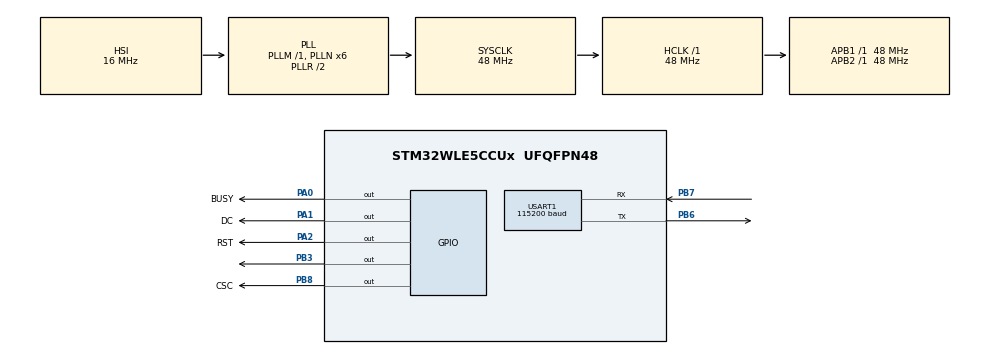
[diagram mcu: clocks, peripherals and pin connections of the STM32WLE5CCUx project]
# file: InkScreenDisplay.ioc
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Dma.Request0=USART1_RX
Dma.Request1=USART1_TX
Dma.USART1_RX.0.Direction=DMA_PERIPH_TO_MEMORY
Dma.USART1_RX.0.EventEnable=DISABLE
Dma.USART1_RX.0.Instance=DMA1_Channel1
Dma.USART1_RX.0.MemDataAlignment=DMA_MDATAALIGN_BYTE
Dma.USART1_RX.0.MemInc=DMA_MINC_ENABLE
Dma.USART1_RX.0.Mode=DMA_NORMAL
Dma.USART1_RX.0.PeriphDataAlignment=DMA_PDATAALIGN_BYTE
Dma.USART1_RX.0.PeriphInc=DMA_PINC_DISABLE
Dma.USART1_RX.0.Polarity=HAL_DMAMUX_REQ_GEN_RISING
Dma.USART1_RX.0.Priority=DMA_PRIORITY_HIGH
Dma.USART1_RX.0.RequestNumber=1
Dma.USART1_RX.0.SignalID=NONE
Dma.USART1_RX.0.SyncEnable=DISABLE
Dma.USART1_RX.0.SyncPolarity=HAL_DMAMUX_SYNC_NO_EVENT
Dma.USART1_RX.0.SyncRequestNumber=1
Dma.USART1_RX.0.SyncSignalID=NONE
Dma.USART1_TX.1.Direction=DMA_MEMORY_TO_PERIPH
Dma.USART1_TX.1.EventEnable=DISABLE
Dma.USART1_TX.1.Instance=DMA1_Channel2
Dma.USART1_TX.1.MemDataAlignment=DMA_MDATAALIGN_BYTE
Dma.USART1_TX.1.MemInc=DMA_MINC_ENABLE
Dma.USART1_TX.1.Mode=DMA_NORMAL
Dma.USART1_TX.1.PeriphDataAlignment=DMA_PDATAALIGN_BYTE
Dma.USART1_TX.1.PeriphInc=DMA_PINC_DISABLE
Dma.USART1_TX.1.Polarity=HAL_DMAMUX_REQ_GEN_RISING
Dma.USART1_TX.1.Priority=DMA_PRIORITY_LOW
Dma.USART1_TX.1.RequestNumber=1
Dma.USART1_TX.1.SignalID=NONE
Dma.USART1_TX.1.SyncEnable=DISABLE
Dma.USART1_TX.1.SyncPolarity=HAL_DMAMUX_SYNC_NO_EVENT
Dma.USART1_TX.1.SyncRequestNumber=1
Dma.USART1_TX.1.SyncSignalID=NONE
Mcu.Family=STM32WL
Mcu.Name=STM32WLE5CCUx
Mcu.Package=UFQFPN48
NVIC.DMA1_Channel1_IRQn=true\:0\:0\:false\:false\:true\:false\:true\:true
NVIC.DMA1_Channel2_IRQn=true\:0\:0\:false\:false\:true\:false\:true\:true
NVIC.PriorityGroup=NVIC_PRIORITYGROUP_4
NVIC.USART1_IRQn=true\:0\:0\:false\:false\:true\:true\:true\:true
PA0.GPIO_Label=BUSY
PA0.Signal=GPIO_Output
PA1.GPIO_Label=DC
PA1.Signal=GPIO_Output
PA13.Mode=Serial_Wire
PA13.Signal=DEBUG_JTMS-SWDIO
PA14.Mode=Serial_Wire
PA14.Signal=DEBUG_JTCK-SWCLK
PA2.GPIO_Label=RST
PA2.Signal=GPIO_Output
PB3.Signal=GPIO_Output
PB6.Mode=Asynchronous
PB6.Signal=USART1_TX
PB7.Mode=Asynchronous
PB7.Signal=USART1_RX
PB8.GPIO_Label=CSC
PB8.Signal=GPIO_Output
ProjectManager.HeapSize=0x200
ProjectManager.StackSize=0x400
ProjectManager.TargetToolchain=MDK-ARM V5.37
RCC.AHBFreq_Value=48000000
RCC.APB1Freq_Value=48000000
RCC.APB1TimFreq_Value=48000000
RCC.APB2Freq_Value=48000000
RCC.APB2TimFreq_Value=48000000
RCC.APB3Freq_Value=48000000
RCC.CortexFreq_Value=48000000
RCC.HCLKFreq_Value=48000000
RCC.HSE_VALUE=16000000
RCC.HSI_VALUE=16000000
RCC.LSE_VALUE=32768
RCC.LSIDIV=RCC_LSI_DIV128
RCC.MSIClockRange=RCC_MSIRANGE_0
RCC.PLLN=6
RCC.PLLSourceVirtual=RCC_PLLSOURCE_HSI
RCC.SYSCLKFreq_VALUE=48000000
RCC.SYSCLKSource=RCC_SYSCLKSOURCE_PLLCLK
RCC.USART1CLockSelection=RCC_USART1CLKSOURCE_SYSCLK
RCC.VCOOutputFreq_Value=96000000
USART1.BaudRate=115200
USART1.VirtualMode-Asynchronous=VM_ASYNC
board=custom

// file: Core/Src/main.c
/* USER CODE BEGIN Header */
/**
 ******************************************************************************
 * @file           : main.c
 * @brief          : Main program body
 ******************************************************************************
 * @attention
 *
 * Copyright (c) 2024 STMicroelectronics.
 * All rights reserved.
 *
 * This software is licensed under terms that can be found in the LICENSE file
 * in the root directory of this software component.
 * If no LICENSE file comes with this software, it is provided AS-IS.
 *
 ******************************************************************************
 */
/* USER CODE END Header */
#include "main.h"
#include "dma.h"
#include "usart.h"
#include "gpio.h"

/* USER CODE BEGIN Includes */
#include <string.h>
/* USER CODE END Includes */

void SystemClock_Config(void);
/* USER CODE BEGIN PFP */
int fputc( int ch, FILE* f ) {
    HAL_UART_Transmit( &huart1, ( uint8_t* )&ch, 1, 0xffff );
    return ch;
}

int fgetc( FILE* f ) {
    uint8_t ch = 0;
    HAL_UART_Receive( &huart1, &ch, 1, 0xffff );
    return ch;
}
/* USER CODE END PFP */

int main(void)
{

  /* MCU Configuration--------------------------------------------------------*/

  /* Reset of all peripherals, Initializes the Flash interface and the Systick. */
  HAL_Init();

  /* Configure the system clock */
  SystemClock_Config();

  /* Initialize all configured peripherals */
  MX_GPIO_Init();
  MX_DMA_Init();
  MX_USART1_UART_Init();

  /* Infinite loop */
  /* USER CODE BEGIN WHILE */
    while ( 1 ) {
        printf("hello world\r\n");
			HAL_Delay(1000);
    /* USER CODE END WHILE */

    }
}

void SystemClock_Config(void)
{
  RCC_OscInitTypeDef RCC_OscInitStruct = {0};
  RCC_ClkInitTypeDef RCC_ClkInitStruct = {0};

  /** Configure the main internal regulator output voltage
  */
  __HAL_PWR_VOLTAGESCALING_CONFIG(PWR_REGULATOR_VOLTAGE_SCALE1);

  /** Initializes the CPU, AHB and APB buses clocks
  */
  RCC_OscInitStruct.OscillatorType = RCC_OSCILLATORTYPE_HSI;
  RCC_OscInitStruct.HSIState = RCC_HSI_ON;
  RCC_OscInitStruct.HSICalibrationValue = RCC_HSICALIBRATION_DEFAULT;
  RCC_OscInitStruct.PLL.PLLState = RCC_PLL_ON;
  RCC_OscInitStruct.PLL.PLLSource = RCC_PLLSOURCE_HSI;
  RCC_OscInitStruct.PLL.PLLM = RCC_PLLM_DIV1;
  RCC_OscInitStruct.PLL.PLLN = 6;
  RCC_OscInitStruct.PLL.PLLP = RCC_PLLP_DIV2;
  RCC_OscInitStruct.PLL.PLLR = RCC_PLLR_DIV2;
  RCC_OscInitStruct.PLL.PLLQ = RCC_PLLQ_DIV2;
  if (HAL_RCC_OscConfig(&RCC_OscInitStruct) != HAL_OK)
  {
    Error_Handler();
  }

  /** Configure the SYSCLKSource, HCLK, PCLK1 and PCLK2 clocks dividers
  */
  RCC_ClkInitStruct.ClockType = RCC_CLOCKTYPE_HCLK3|RCC_CLOCKTYPE_HCLK
                              |RCC_CLOCKTYPE_SYSCLK|RCC_CLOCKTYPE_PCLK1
                              |RCC_CLOCKTYPE_PCLK2;
  RCC_ClkInitStruct.SYSCLKSource = RCC_SYSCLKSOURCE_PLLCLK;
  RCC_ClkInitStruct.AHBCLKDivider = RCC_SYSCLK_DIV1;
  RCC_ClkInitStruct.APB1CLKDivider = RCC_HCLK_DIV1;
  RCC_ClkInitStruct.APB2CLKDivider = RCC_HCLK_DIV1;
  RCC_ClkInitStruct.AHBCLK3Divider = RCC_SYSCLK_DIV1;

  if (HAL_RCC_ClockConfig(&RCC_ClkInitStruct, FLASH_LATENCY_2) != HAL_OK)
  {
    Error_Handler();
  }
}

void Error_Handler(void)
{
    __disable_irq();
    while ( 1 ) {
    }
}
